# SPI0_1.0 register map
Vendor: Texas Instruments
Peripheral module from a debugger description file (folder mspm0g1x0x_g3x0x).
Registers are 32-bit, read-write, no defined reset value unless marked. A register's access mark holds for its fields unless they carry their own. Offsets are as the file gives them; lines under a group give offsets from that group; [hi:lo] are bit positions; {n}, {i} and the like mark numbered series; 'fields as' and 'values as' point back to an identical list; <NAME> marks a mode.

## SPI0
0x800 SPI0_GPRCM group
  0x00 SPI0_PWREN — Power enable
    [0] ENABLE — Enable the power
      0=DISABLE (Disable Power); 1=ENABLE (Enable Power)
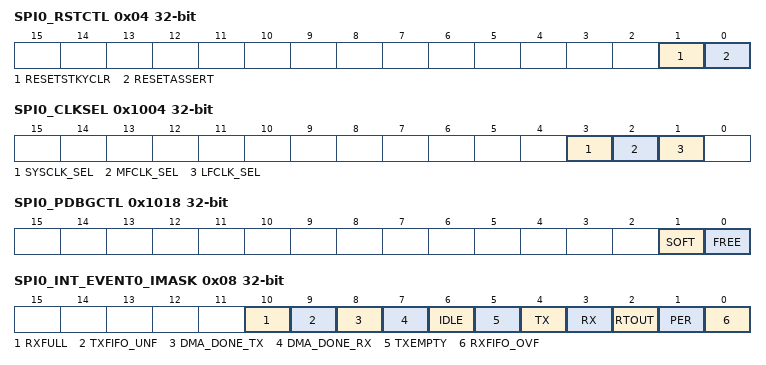
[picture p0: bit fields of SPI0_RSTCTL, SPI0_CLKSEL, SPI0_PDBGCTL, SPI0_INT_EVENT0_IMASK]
  0x04 SPI0_RSTCTL — Reset Control
    [1] RESETSTKYCLR — Clear the RESETSTKY bit in the STAT register
      0=NOP (Writing 0 has no effect); 1=CLR (Clear reset sticky bit)
    [0] RESETASSERT — Assert reset to the peripheral
      0=NOP (Writing 0 has no effect); 1=ASSERT (Assert reset)
  0x08 SPI0_CLKCFG — Peripheral Clock Configuration Register
    [8] BLOCKASYNC — Async Clock Request is blocked from starting SYSOSC or forcing bus clock to 32MHz
      0=DISABLE (Not block async clock request); 1=ENABLE (Block async clock request)
  0x14 SPI0_GPRCM_STAT ro — Status Register
    [16] RESETSTKY — This bit indicates, if the peripheral was reset, since this bit was cleared by RESETSTKYCLR in the RSTCTL register
      0=NORES (The peripheral has not been reset since this bit was last cleared by RESETSTKYCLR in the RSTCTL register); 1=RESET (The peripheral was reset since the last bit clear)
0x1000 SPI0_CLKDIV — Clock Divider
  [2:0] RATIO — Selects divide ratio of module clock
    0=DIV_BY_1 (Do not divide clock source); {v}=DIV_BY_{v+1} (Divide clock source by {v+1}) (v=1..7)
0x1004 SPI0_CLKSEL — Clock Select for Ultra Low Power peripherals
  [all] fields
    0=DISABLE (Does not select this clock as a source); 1=ENABLE (Select this clock as a source)
  [3] SYSCLK_SEL — Selects SYSCLK as clock source if enabled
  [2] MFCLK_SEL — Selects MFCLK as clock source if enabled
  [1] LFCLK_SEL — Selects LFCLK as clock source if enabled
0x1018 SPI0_PDBGCTL — Peripheral Debug Control
  [1] SOFT — Soft halt boundary control. This function is only available, if [FREE] is set to 'STOP'
    0=IMMEDIATE (The peripheral will halt immediately, even if the resultant state will result in corruption if the system is restarted); 1=DELAYED (The peripheral blocks the debug freeze until it has reached a boundary where it can resume without corruption)
  [0] FREE — Free run control
    0=STOP (The peripheral freezes functionality while the Core Halted input is asserted and resumes when it is deasserted.); 1=RUN (The peripheral ignores the state of the Core Halted input)
0x1020 SPI0_INT_EVENT0 group
  0x00 SPI0_INT_EVENT0_IIDX ro — Interrupt Index Register
    [7:0] STAT — Interrupt index status
      0=NO_INTR (No interrupt pending); 1=RXFIFO_OFV_EVT (RX FIFO Overflow Event/interrupt pending); 2=PER_EVT (Transmit Parity Event/interrupt pending); 3=RTOUT_EVT (SPI receive time-out interrupt); 4=RX_EVT (Receive Event/interrupt pending); 5=TX_EVT (Transmit Event/interrupt pending); 6=TX_EMPTY (Transmit Buffer Empty Event/interrupt pending); 7=IDLE_EVT (End of Transmit Event/interrupt pending); 8=DMA_DONE_RX_EVT (DMA Done for Recevive Event/interrupt pending); 9=DMA_DONE_TX_EVT (DMA Done for Transmit Event/interrupt pending); 10=TXFIFO_UNF_EVT (TX FIFO underflow interrupt); 11=RXFULL_EVT (RX FIFO Full Interrupt)
  0x08 SPI0_INT_EVENT0_IMASK — Interrupt mask
    [all] fields
      0=CLR (Clear Interrupt Mask); 1=SET (Set Interrupt Mask)
    [10] RXFULL — RX FIFO Full Interrupt Mask
    [9] TXFIFO_UNF — TX FIFO underflow interrupt mask
    [8] DMA_DONE_TX — DMA Done 1 event for TX event mask.
    [7] DMA_DONE_RX — DMA Done 1 event for RX event mask.
    [6] IDLE — SPI Idle event mask.
    [5] TXEMPTY — Transmit FIFO Empty event mask.
    [4] TX — Transmit FIFO event mask.
    [3] RX — Receive FIFO event.This interrupt is set if the selected Receive FIFO level has been reached
    [2] RTOUT — Enable SPI Receive Time-Out event mask.
    [1] PER — Parity error event mask.
    [0] RXFIFO_OVF — RXFIFO overflow event mask.
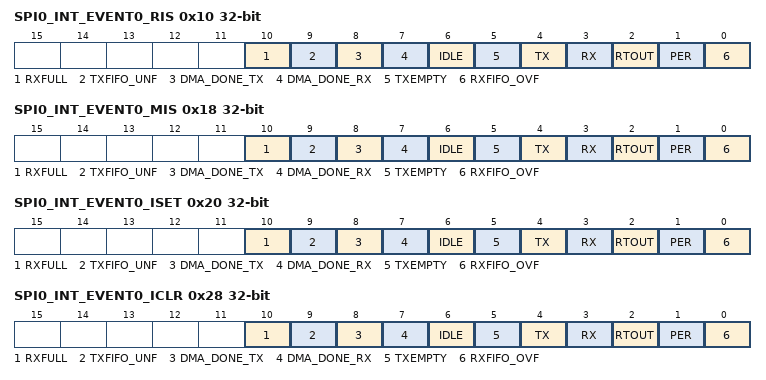
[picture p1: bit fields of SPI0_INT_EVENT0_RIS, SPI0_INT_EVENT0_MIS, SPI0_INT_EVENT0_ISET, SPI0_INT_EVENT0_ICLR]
  0x10 SPI0_INT_EVENT0_RIS — Raw interrupt status
    [all] fields
      0=CLR (Interrupt did not occur); 1=SET (Interrupt occurred)
    [10] RXFULL — RX FIFO Full Interrupt
    [9] TXFIFO_UNF — TX FIFO Underflow Interrupt
    [8] DMA_DONE_TX — DMA Done 1 event for TX. This interrupt is set if the TX DMA channel sends the DONE signal. This allows the handling of the DMA event inside the mapped peripheral.
    [7] DMA_DONE_RX — DMA Done 1 event for RX. This interrupt is set if the RX DMA channel sends the DONE signal. This allows the handling of the DMA event inside the mapped peripheral.
    [6] IDLE — SPI has done finished transfers and changed into IDLE mode. This bit is set when BUSY goes low.
    [5] TXEMPTY — Transmit FIFO Empty interrupt mask. This interrupt is set if all data in the Transmit FIFO have been move to the shift register.
    [4] TX — Transmit FIFO event..This interrupt is set if the selected Transmit FIFO level has been reached.
    [3] RX — Receive FIFO event.This interrupt is set if the selected Receive FIFO level has been reached
    [2] RTOUT — SPI Receive Time-Out event.
    [1] PER — Parity error event: this bit is set if a Parity error has been detected
    [0] RXFIFO_OVF — RXFIFO overflow event. This interrupt is set if an RX FIFO overflow has been detected.
  0x18 SPI0_INT_EVENT0_MIS — Masked interrupt status
    [10] RXFULL — RX FIFO Full Interrupt
      0=CLR (Interrupt did not occur); 1=SET (Interrupt occurred)
    [9] TXFIFO_UNF — TX FIFO underflow interrupt
      0=CLR (Interrupt did not occur); 1=SET (Interrupt occurred)
    [8] DMA_DONE_TX — Masked DMA Done 1 event for TX.
      0=CLR (Interrupt did not occur); 1=SET (Interrupt occurred)
    [7] DMA_DONE_RX — Masked DMA Done 1 event for RX.
      0=CLR (Interrupt did not occur); 1=SET (Interrupt occurred)
    [6] IDLE — Masked SPI IDLE mode event.
      0=CLR (Interrupt did not occur); 1=SET (Interrupt occurred)
    [5] TXEMPTY — Masked Transmit FIFO Empty event.
      0=CLR (Interrupt did not occur); 1=SET (Interrupt occurred)
    [4] TX — Masked Transmit FIFO event. This interrupt is set if the selected Transmit FIFO level has been reached.
      0=CLR (Interrupt did not occur); 1=SET (Interrupt occurred)
    [3] RX — Masked receive FIFO event.This interrupt is set if the selected Receive FIFO level has been reached
      0=CLR (Interrupt did not occur); 1=SET (Interrupt occurred)
    [2] RTOUT — Masked SPI Receive Time-Out Interrupt.
      0=CLR (Clear Interrupt Mask); 1=SET (Set Interrupt Mask)
    [1] PER — Masked Parity error event: this bit if a Parity error has been detected
      0=CLR (Interrupt did not occur); 1=SET (Interrupt occurred)
    [0] RXFIFO_OVF — Masked RXFIFO overflow event. This interrupt is set if an RX FIFO overflow has been detected.
      0=CLR (Interrupt did not occur); 1=SET (Interrupt occurred)
  0x20 SPI0_INT_EVENT0_ISET — Interrupt set
    [10] RXFULL — Set RX FIFO Full Event
      0=NO_EFFECT (Writing has no effect); 1=SET (Set Interrupt)
    [9] TXFIFO_UNF — Set TX FIFO Underflow Event
      0=NO_EFFECT (Writing has no effect); 1=SET (Set interrupt)
    [8] DMA_DONE_TX — Set DMA Done 1 event for TX.
      0=NO_EFFECT (Writing 0 has no effect); 1=SET (Set Interrupt)
    [7] DMA_DONE_RX — Set DMA Done 1 event for RX.
      0=NO_EFFECT (Writing 0 has no effect); 1=SET (Set Interrupt)
    [6] IDLE — Set SPI IDLE mode event.
      0=NO_EFFECT (Writing 0 has no effect); 1=SET (Set Interrupt)
    [5] TXEMPTY — Set Transmit FIFO Empty event.
      0=NO_EFFECT (Writing 0 has no effect); 1=SET (Set Interrupt)
    [4] TX — Set Transmit FIFO event.
      0=NO_EFFECT (Writing 0 has no effect); 1=SET (Set Interrupt)
    [3] RX — Set Receive FIFO event.
      0=NO_EFFECT (Writing 0 has no effect); 1=SET (Set Interrupt)
    [2] RTOUT — Set SPI Receive Time-Out Event.
      0=NO_EFFECT (Writing 0 has no effect); 1=SET (Set Interrupt Mask)
    [1] PER — Set Parity error event.
      0=NO_EFFECT (Writing 0 has no effect); 1=SET (Set Interrupt)
    [0] RXFIFO_OVF — Set RXFIFO overflow event.
      0=NO_EFFECT (Writing 0 has no effect); 1=SET (Set Interrupt)
  0x28 SPI0_INT_EVENT0_ICLR — Interrupt clear
    [10] RXFULL — Clear RX FIFO underflow event
      0=NO_EFFECT (Writing has no effect); 1=CLR (Clear interrupt)
    [9] TXFIFO_UNF — Clear TXFIFO underflow event
      0=NO_EFFECT (Writing has no effect); 1=CLR (Clear interrupt)
    [8] DMA_DONE_TX — Clear DMA Done 1 event for TX.
      0=NO_EFFECT (Writing 0 has no effect); 1=CLR (Clear Interrupt)
    [7] DMA_DONE_RX — Clear DMA Done 1 event for RX.
      values as DMA_DONE_TX
    [6] IDLE — Clear SPI IDLE mode event.
      values as DMA_DONE_TX
    [5] TXEMPTY — Clear Transmit FIFO Empty event.
      values as DMA_DONE_TX
    [4] TX — Clear Transmit FIFO event.
      values as DMA_DONE_TX
    [3] RX — Clear Receive FIFO event.
      values as DMA_DONE_TX
    [2] RTOUT — Clear SPI Receive Time-Out Event.
      0=NO_EFFECT (Writing 0 has no effect); 1=CLR (Set Interrupt Mask)
    [1] PER — Clear Parity error event.
      values as DMA_DONE_TX
    [0] RXFIFO_OVF — Clear RXFIFO overflow event.
      values as DMA_DONE_TX
0x1050 SPI0_INT_EVENT1 group
  0x00 SPI0_INT_EVENT1_IIDX ro — Interrupt Index Register
    [7:0] STAT — Interrupt index status
      0=NO_INTR (No interrupt pending); 3=RTOUT_EVT (SPI receive time-out interrupt); 4=RX_EVT (Receive Event/interrupt pending)
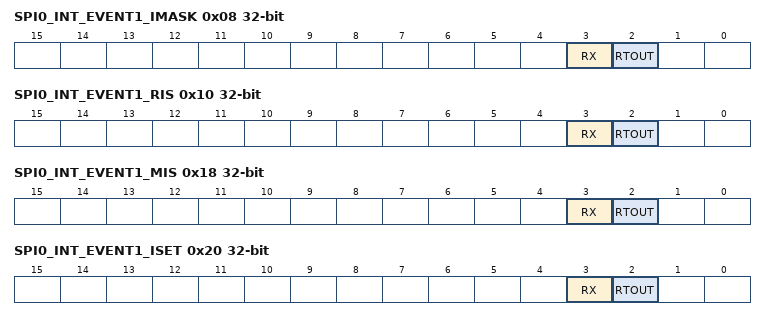
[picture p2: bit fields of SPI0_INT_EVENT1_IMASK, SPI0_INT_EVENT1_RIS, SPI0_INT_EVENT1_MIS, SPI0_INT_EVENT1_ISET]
  0x08 SPI0_INT_EVENT1_IMASK — Interrupt mask
    [3] RX — Receive FIFO event mask.
      0=CLR (Clear Interrupt Mask); 1=SET (Set Interrupt Mask)
    [2] RTOUT — SPI Receive Time-Out event mask.
      0=CLR (Clear Interrupt Mask); 1=SET (Set Interrupt Mask)
  0x10 SPI0_INT_EVENT1_RIS — Raw interrupt status
    [3] RX — Receive FIFO event.This interrupt is set if the selected Receive FIFO level has been reached
      0=CLR (Interrupt did not occur); 1=SET (Interrupt occurred)
    [2] RTOUT — SPI Receive Time-Out Event.
      0=CLR (Clear Interrupt Mask); 1=SET (Set Interrupt Mask)
  0x18 SPI0_INT_EVENT1_MIS — Masked interrupt status
    [3] RX — Receive FIFO event mask.
      0=CLR (Interrupt did not occur); 1=SET (Interrupt occurred)
    [2] RTOUT — SPI Receive Time-Out event mask.
      0=CLR (Clear Interrupt Mask); 1=SET (Set Interrupt Mask)
  0x20 SPI0_INT_EVENT1_ISET — Interrupt set
    [3] RX — Set Receive FIFO event.
      0=NO_EFFECT (Writing 0 has no effect); 1=SET (Set Interrupt)
    [2] RTOUT — Set SPI Receive Time-Out event.
      values as SPI0_INT_EVENT0.SPI0_INT_EVENT0_ISET.RTOUT
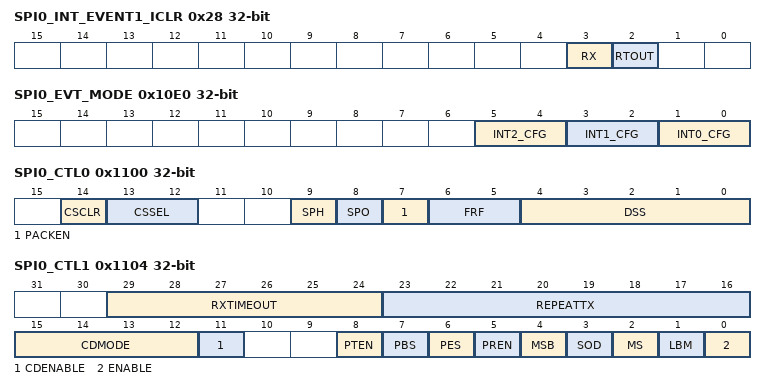
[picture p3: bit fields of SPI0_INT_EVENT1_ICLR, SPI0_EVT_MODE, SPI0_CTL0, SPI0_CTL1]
  0x28 SPI0_INT_EVENT1_ICLR — Interrupt clear
    [3] RX — Clear Receive FIFO event.
      values as SPI0_INT_EVENT0.SPI0_INT_EVENT0_ICLR.DMA_DONE_TX
    [2] RTOUT — Clear SPI Receive Time-Out event.
      values as SPI0_INT_EVENT0.SPI0_INT_EVENT0_ICLR.RTOUT
0x1080 SPI0_INT_EVENT2 group
  0x00 SPI0_INT_EVENT2_IIDX ro — Interrupt Index Register
    [7:0] STAT — Interrupt index status
      0=NO_INTR (No interrupt pending); 5=TX_EVT (Transmit Event/interrupt pending)
  0x08 SPI0_INT_EVENT2_IMASK — Interrupt mask
    [4] TX — Transmit FIFO event mask.
      0=CLR (Clear Interrupt Mask); 1=SET (Set Interrupt Mask)
  0x10 SPI0_INT_EVENT2_RIS — Raw interrupt status
    [4] TX — Transmit FIFO event: A read returns the current mask for transmit FIFO interrupt. On a write of 1, the mask for transmit FIFO interrupt is set which means the interrupt state will be reflected in MIS.TXMIS. A write of 0 clears the mask which means MIS.TXMIS will not reflect the interrupt.
      0=CLR (Interrupt did not occur); 1=SET (Interrupt occurred)
  0x18 SPI0_INT_EVENT2_MIS — Masked interrupt status
    [4] TX — Masked Transmit FIFO event
      0=CLR (Interrupt did not occur); 1=SET (Interrupt occurred)
  0x20 SPI0_INT_EVENT2_ISET — Interrupt set
    [4] TX — Set Transmit FIFO event.
      0=NO_EFFECT (Writing 0 has no effect); 1=SET (Set Interrupt)
  0x28 SPI0_INT_EVENT2_ICLR — Interrupt clear
    [4] TX — Clear Transmit FIFO event.
      values as SPI0_INT_EVENT0.SPI0_INT_EVENT0_ICLR.DMA_DONE_TX
0x10E0 SPI0_EVT_MODE ro — Event Mode
  [all] fields
    0=DISABLE (The interrupt or event line is disabled.); 1=SOFTWARE (The interrupt or event line is in software mode. Software must clear the RIS.); 2=HARDWARE (The interrupt or event line is in hardware mode. The hardware (another module) clears automatically the associated RIS flag.)
  [5:4] INT2_CFG — Event line mode select for event corresponding to [IPSTANDARD.INT_EVENT2]
  [3:2] INT1_CFG — Event line mode select for event corresponding to [IPSTANDARD.INT_EVENT1]
  [1:0] INT0_CFG — Event line mode select for event corresponding to [IPSTANDARD.INT_EVENT0]
0x10E4 SPI0_INTCTL — Interrupt control register
  [0] INTEVAL — Writing a 1 to this field re-evaluates the interrupt sources.
    0=DISABLE (The interrupt or event line is disabled.); 1=EVAL (The interrupt or event line is in software mode. Software must clear the RIS.)
0x1100 SPI0_CTL0 — SPI control register 0
  [14] CSCLR — Clear shift register counter on CS inactive This bit is relevant only in the peripheral, CTL1.MS=0.
    0=DISABLE (Disable automatic clear of shift register when CS goes to disable.); 1=ENABLE (Enable automatic clear of shift register when CS goes to disable.)
  [13:12] CSSEL — Select the CS line to control on data transfer This bit is for controller mode only.
    {v}=CS line select: {v} (v=0..3)
  [9] SPH — CLKOUT phase (Motorola SPI frame format only) This bit selects the clock edge that captures data and enables it to change state. It has the most impact on the first bit transmitted by either permitting or not permitting a clock transition before the first data capture edge.
    0=FIRST (Data is captured on the first clock edge transition.); 1=SECOND (Data is captured on the second clock edge transition.)
  [8] SPO — CLKOUT polarity (Motorola SPI frame format only)
    0=LOW (SPI produces a steady state LOW value on the CLKOUT); 1=HIGH (SPI produces a steady state HIGH value on the CLKOUT)
  [7] PACKEN — Packing Enable. When 1, packing feature is enabled inside the IP When 0, packing feature is disabled inside the IP
    0=DISABLED (Packing feature disabled); 1=ENABLED (Packing feature enabled)
  [6:5] FRF — Frame format Select
    0=MOTOROLA_3WIRE (Motorola SPI frame format (3 wire mode)); 1=MOTOROLA_4WIRE (Motorola SPI frame format (4 wire mode)); 2=TI_SYNC (TI synchronous serial frame format); 3=MIRCOWIRE (National Microwire frame format)
  [4:0] DSS — Data Size Select. Values 0 - 2 are reserved and shall not be used. 3h = 4_BIT : 4-bit data SPI allows only values up to 16 Bit
    {v}=Data Size Select bits: {v+1} (v=3..15); 31=Data Size Select bits: 32
0x1104 SPI0_CTL1 — SPI control register 1
  [29:24] RXTIMEOUT — Receive Timeout (only for Peripheral mode) Defines the number of Clock Cycles before after which the Receive Timeout flag RTOUT is set. The time is calculated using the control register for the clock selection and divider in the Controller mode configuration. A value of 0 disables this function.
    0=MINIMUM (Smallest value); 63=MAXIMUM (Highest possible value)
  [23:16] REPEATTX — Counter to repeat last transfer 0: repeat last transfer is disabled. x: repeat the last transfer with the given number. The transfer will be started with writing a data into the TX Buffer. Sending the data will be repeated with the given value, so the data will be transferred X+1 times in total. The behavior is identical as if the data would be written into the TX Buffer that many times as defined by the value here. It can be used to clean a transfer or to pull a certain amount of data by a peripheral.
    0=DISABLE (REPEATTX disable); 0=MINIMUM (Smallest value); 255=MAXIMUM (Highest possible value)
  [15:12] CDMODE — Command/Data Mode Value When CTL1.CDENABLE is 1, CS3 line is used as C/D signal to distinguish between Command (C/D low) and Data (C/D high) information. When a value is written into the CTL1.CDMODE bits, the C/D (CS3) line will go low for the given numbers of byte which are sent by the SPI, starting with the next value to be transmitted after which, C/D line will go high automatically 0: Manual mode with C/D signal as High 1-14: C/D is low while this number of bytes are being sent after which, this field sets to 0 and C/D goes high. Reading this field at any time returns the remaining number of command bytes. 15: Manual mode with C/D signal as Low.
    0=MINIMUM (Smallest value); 0=DATA (Manual mode: Data); 15=MAXIMUM (Highest possible value); 15=COMMAND (Manual mode: Command)
  [11] CDENABLE — Command/Data Mode enable
    0=DISABLE (CS3 is used for Chip Select); 1=ENABLE (CS3 is used as CD signal)
  [8] PTEN — Parity transmit enable If enabled, parity transmission will be done for both controller and peripheral modes.
    0=DISABLE (Parity transmission is disabled); 1=ENABLE (Parity transmission is enabled)
  [7] PBS — Parity Bit Select
    0=DISABLE (Bit 0 is used for Parity); 1=ENABLE (Bit 1 is used for Parity, Bit 0 is ignored)
  [6] PES — Even Parity Select
    0=DISABLE (Odd Parity mode); 1=ENABLE (Even Parity mode)
  [5] PREN — Parity receive enable If enabled, parity reception check will be done for both controller and peripheral modes In case of a parity miss-match the parity error flag RIS.PER will be set.
    0=DISABLE (Disable Parity receive function); 1=ENABLE (Enable Parity receive function)
  [4] MSB — MSB first select. Controls the direction of the receive and transmit shift register.
    0=DISABLE (LSB first); 1=ENABLE (MSB first)
  [3] SOD — Peripheral-mode: Data output disabled This bit is relevant only in the peripheral mode, CTL1.MS=1. In multiple-peripheral systems, it is possible for an SPI controller to broadcast a message to all peripherals in the system while ensuring that only one peripheral drives data onto its serial output line. In such systems the MISO lines from multiple peripherals could be tied together. To operate in such systems, this bitfield can be set if the SPI peripheral is not supposed to drive the MISO line:
    0=DISABLE (SPI can drive the MISO output in peripheral mode.); 1=ENABLE (SPI cannot drive the MISO output in peripheral mode.)
  [2] MS — Controller or peripheral mode select. This bit can be modified only when SPI is disabled, CTL1.ENABLE=0.
    0=DISABLE (Select Peripheral mode); 1=ENABLE (Select Controller Mode)
  [1] LBM — Loop back mode
    0=DISABLE (Disable loopback mode); 1=ENABLE (Enable loopback mode)
  [0] ENABLE — SPI enable
    0=DISABLE (Disable module function); 1=ENABLE (Enable module function)
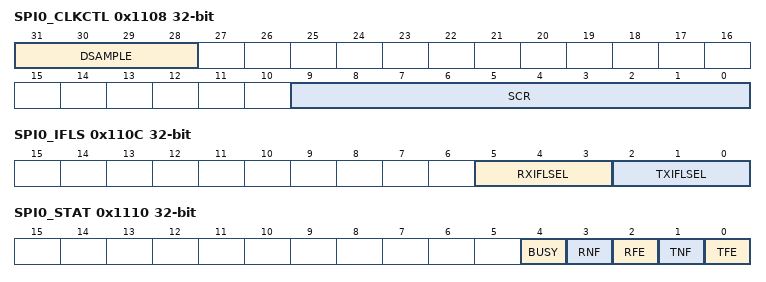
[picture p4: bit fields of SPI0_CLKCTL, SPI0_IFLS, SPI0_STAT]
0x1108 SPI0_CLKCTL — Clock prescaler and divider register.
  [31:28] DSAMPLE — Delayed sampling value. In controller mode the data on the input pin will be delayed sampled by the defined clock cycles of internal functional clock hence relaxing the setup time of input data. This setting is useful in systems where the board delays and external peripheral delays are more than the input setup time of the controller. Please refer to the datasheet for values of controller input setup time and assess what DSAMPLE value meets the requirement of the system. Note: High values of DSAMPLE can cause HOLD time violations and must be factored in the calculations.
    0=MINIMUM (Smallest value); 15=MAXIMUM (Highest possible value)
  [9:0] SCR — Serial clock divider: This is used to generate the transmit and receive bit rate of the SPI. The SPI bit rate is (SPI's functional clock frequency)/((SCR+1)*2). SCR is a value from 0-1023.
    0=MINIMUM (Smallest value); 0x3FF=MAXIMUM (Highest possible value)
0x110C SPI0_IFLS — UART Interrupt FIFO Level Select Register
  [5:3] RXIFLSEL — SPI Receive Interrupt FIFO Level Select The trigger points for the receive interrupt are as follows:
    0=LVL_OFF (Reserved); 1=LVL_1_4 (RX FIFO >= 1/4 full); 2=LVL_1_2 (RX FIFO >= 1/2 full (default)); 3=LVL_3_4 (RX FIFO >= 3/4 full); 4=LVL_RES4 (Reserved); 5=LVL_FULL (RX FIFO is full); 6=LVL_RES6 (Reserved); 7=LEVEL_1 (Trigger when RX FIFO contains >= 1 frame)
  [2:0] TXIFLSEL — SPI Transmit Interrupt FIFO Level Select The trigger points for the transmit interrupt are as follows:
    0=LVL_OFF (Reserved); 1=LVL_3_4 (TX FIFO <= 3/4 empty); 2=LVL_1_2 (TX FIFO <= 1/2 empty (default)); 3=LVL_1_4 (TX FIFO <= 1/4 empty); 4=LVL_RES4 (Reserved); 5=LVL_EMPTY (TX FIFO is empty); 6=LVL_RES6 (Reserved); 7=LEVEL_1 (Trigger when TX FIFO has >= 1 frame free Should be used with DMA)
0x1110 SPI0_STAT — Status Register
  [4] BUSY
    0=IDLE (SPI is in idle mode.); 1=ACTIVE (SPI is currently transmitting and/or receiving data, or transmit FIFO is not empty.)
  [3] RNF — Receive FIFO not full
    0=FULL (Receive FIFO is full.); 1=NOT_FULL (Receive FIFO is not full.)
  [2] RFE — Receive FIFO empty.
    0=NOT_EMPTY (Receive FIFO is not empty.); 1=EMPTY (Receive FIFO is empty.)
  [1] TNF — Transmit FIFO not full
    0=FULL (Transmit FIFO is full.); 1=NOT_FULL (Transmit FIFO is not full.)
  [0] TFE — Transmit FIFO empty.
    0=NOT_EMPTY (Transmit FIFO is not empty.); 1=EMPTY (Transmit FIFO is empty.)
0x1130 SPI0_RXDATA ro — RXDATA Register
  [15:0] DATA — Received Data When PACKEN=1,two entries of the FIFO are returned as a 32-bit value. When PACKEN=0, 1 entry of FIFO is returned as 16-bit value. As data values are removed by the receive logic from the incoming data frame, they are placed into the entry in the receive FIFO, pointed to by the current FIFO write pointer. Received data less than 16 bits is automatically right justified in the receive buffer.
0x1140 SPI0_TXDATA — TXDATA Register
  [15:0] DATA — Transmit Data WWhen read, last written value will be returned. If the last write to this field was a 32-bit write (with PACKEN=1), 32-bits will be returned and if the last write was a 16-bit write (PACKEN=0), those 16-bits will be returned. When written, one or two FIFO entries will be written depending on PACKEN value. Data values are removed from the transmit FIFO one value at a time by the transmit logic. It is loaded into the transmit serial shifter, then serially shifted out onto the TXD output pin at the programmed bit rate. When a data size of less than 16 bits is selected, the user must right-justify data written to the transmit FIFO. The transmit logic ignores the unused bits.
